# ADSP-2183xW_HPC register map
Vendor: Analog Devices; Series: ADSP-2183xW_HPC; File version: 3.0.3.517
CPU: 
Registers are 32-bit, read-write, reset 0x0 unless marked. A register's access mark holds for its fields unless they carry their own. Offsets are from the block's base; [hi:lo] are bit positions; {n}, {i} and the like mark numbered series.

## CSETR1
Base 0x3110A000
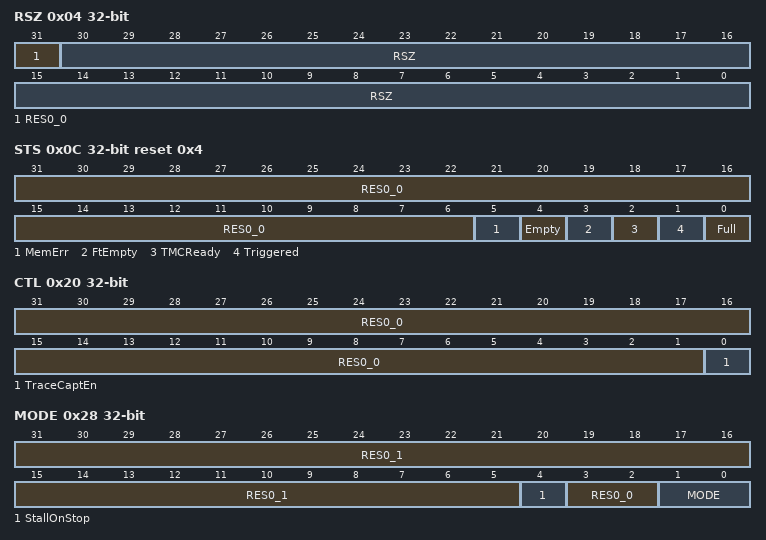
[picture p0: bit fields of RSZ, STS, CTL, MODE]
0x04 RSZ — RAM Size register.
  [31] RES0_0 range 0x00000000..0x00000001, [30:0] RSZ range 0x00000000..0x7FFFFFFF
0x0C STS reset 0x4 — Status register.
  [31:6] RES0_0 range 0x00000000..0x03FFFFFF, [5] MemErr range 0x00000000..0x00000001, [4] Empty ro, [3] FtEmpty ro, [2] TMCReady ro, [1] Triggered ro, [0] Full range 0x00000000..0x00000001
0x10 RRD — RAM Read Data register.
  [31:0] RRD ro
0x14 RRP — RAM Read Pointer register.
  [31:0] RRP range 0x00000000..0xFFFFFFFF
0x18 RWP — RAM Write Pointer register.
  [31:0] RWP range 0x00000000..0xFFFFFFFF
0x1C TRG — Trigger Counter register.
  [31:0] TRG range 0x00000000..0xFFFFFFFF
0x20 CTL — Control Register.
  [31:1] RES0_0 range 0x00000000..0x7FFFFFFF, [0] TraceCaptEn range 0x00000000..0x00000001
0x24 RWD — RAM Write Data register.
  [31:0] RWD wo range 0x00000000..0xFFFFFFFF
0x28 MODE
  [31:5] RES0_1 range 0x00000000..0x07FFFFFF, [4] StallOnStop range 0x00000000..0x00000001, [3:2] RES0_0 range 0x00000000..0x00000003, [1:0] MODE range 0x00000000..0x00000003
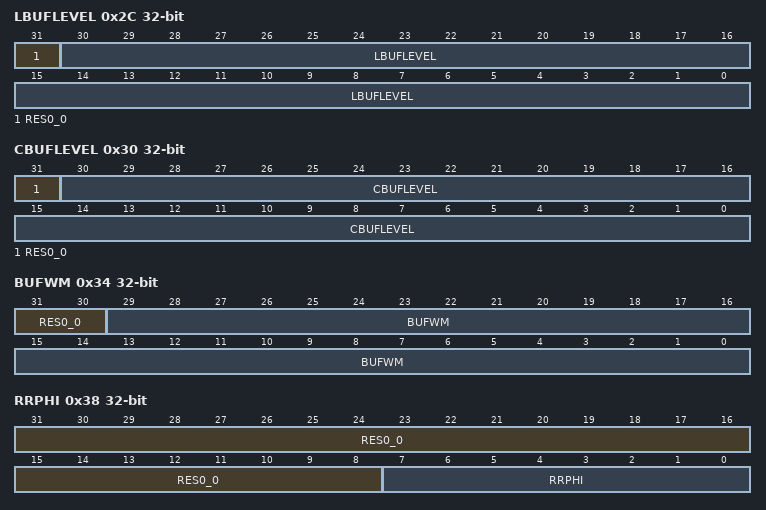
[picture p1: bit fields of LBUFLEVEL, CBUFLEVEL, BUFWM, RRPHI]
0x2C LBUFLEVEL — Latched Buffer Fill Level.
  [31] RES0_0 ro, [30:0] LBUFLEVEL ro
0x30 CBUFLEVEL — Current Buffer Fill Level.
  [31] RES0_0 ro, [30:0] CBUFLEVEL ro
0x34 BUFWM — Buffer Level Water Mark.
  [31:30] RES0_0 range 0x00000000..0x00000003, [29:0] BUFWM range 0x00000000..0x3FFFFFFF
0x38 RRPHI — RAM Read Pointer High register.
  [31:8] RES0_0 range 0x00000000..0x00FFFFFF, [7:0] RRPHI range 0x00000000..0x000000FF
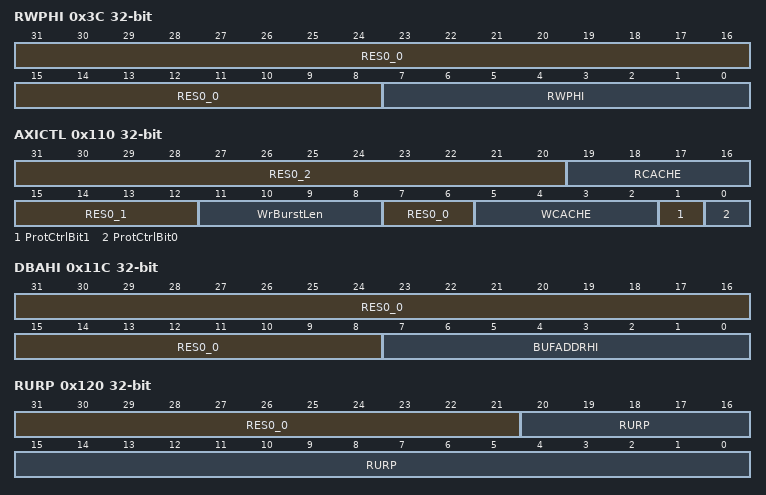
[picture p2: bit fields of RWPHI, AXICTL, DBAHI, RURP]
0x3C RWPHI — RAM Write Pointer High register.
  [31:8] RES0_0 range 0x00000000..0x00FFFFFF, [7:0] RWPHI range 0x00000000..0x000000FF
0x110 AXICTL — AXI Control Register.
  [31:20] RES0_2 range 0x00000000..0x00000FFF, [19:16] RCACHE range 0x00000000..0x0000000F, [15:12] RES0_1 range 0x00000000..0x0000000F, [11:8] WrBurstLen range 0x00000000..0x0000000F, [7:6] RES0_0 range 0x00000000..0x00000003, [5:2] WCACHE range 0x00000000..0x0000000F, [1] ProtCtrlBit1 range 0x00000000..0x00000001, [0] ProtCtrlBit0 range 0x00000000..0x00000001
0x118 DBALO — Data Buffer Address Low register.
  [31:0] BUFADDRLO range 0x00000000..0xFFFFFFFF
0x11C DBAHI — Data Buffer Address HIGH register.
  [31:8] RES0_0 range 0x00000000..0x00FFFFFF, [7:0] BUFADDRHI range 0x00000000..0x000000FF
0x120 RURP — RAM Update Read Pointer register.
  [31:21] RES0_0 wo range 0x00000000..0x000007FF, [20:0] RURP wo range 0x00000000..0x001FFFFF
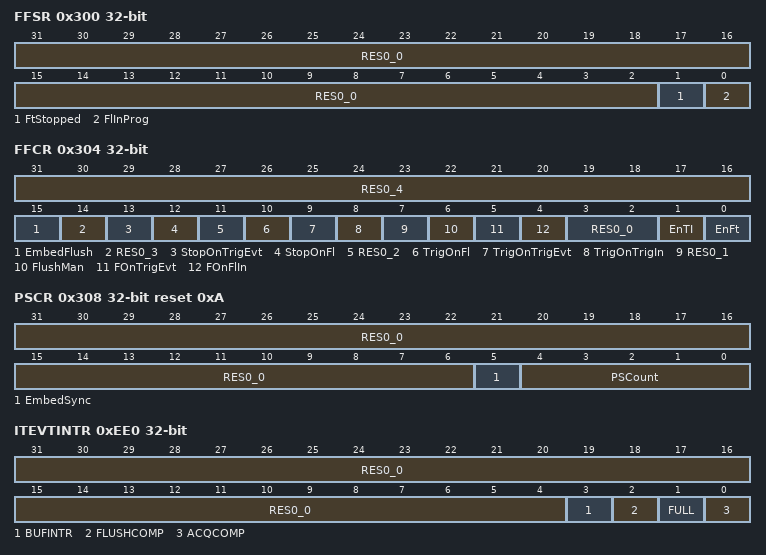
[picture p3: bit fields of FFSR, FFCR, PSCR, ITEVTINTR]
0x300 FFSR — Formatter and Flush Status Register.
  [31:2] RES0_0 ro, [1] FtStopped ro, [0] FlInProg ro
0x304 FFCR — Formatter and Flush Control Register.
  [31:16] RES0_4 range 0x00000000..0x0000FFFF, [15] EmbedFlush range 0x00000000..0x00000001, [14] RES0_3 range 0x00000000..0x00000001, [13] StopOnTrigEvt range 0x00000000..0x00000001, [12] StopOnFl range 0x00000000..0x00000001, [11] RES0_2 range 0x00000000..0x00000001, [10] TrigOnFl range 0x00000000..0x00000001, [9] TrigOnTrigEvt range 0x00000000..0x00000001, [8] TrigOnTrigIn range 0x00000000..0x00000001, [7] RES0_1 range 0x00000000..0x00000001, [6] FlushMan range 0x00000000..0x00000001, [5] FOnTrigEvt range 0x00000000..0x00000001, [4] FOnFlIn range 0x00000000..0x00000001, [3:2] RES0_0 range 0x00000000..0x00000003, [1] EnTI range 0x00000000..0x00000001, [0] EnFt range 0x00000000..0x00000001
0x308 PSCR reset 0xA — Periodic Synchronization Counter Register.
  [31:6] RES0_0 range 0x00000000..0x03FFFFFF, [5] EmbedSync range 0x00000000..0x00000001, [4:0] PSCount range 0x00000000..0x0000001F
0xEE0 ITEVTINTR — Integration Test Event and Interrupt Control Register.
  [31:4] RES0_0 wo range 0x00000000..0x0FFFFFFF, [3] BUFINTR wo range 0x00000000..0x00000001, [2] FLUSHCOMP wo range 0x00000000..0x00000001, [1] FULL wo range 0x00000000..0x00000001, [0] ACQCOMP wo range 0x00000000..0x00000001
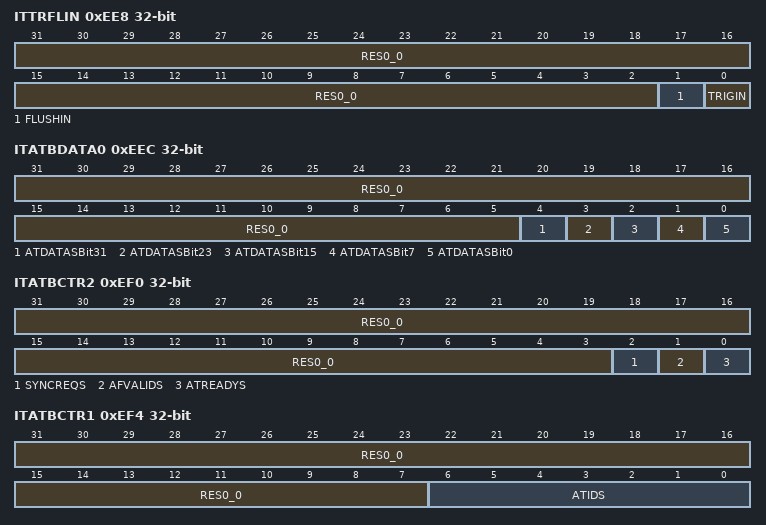
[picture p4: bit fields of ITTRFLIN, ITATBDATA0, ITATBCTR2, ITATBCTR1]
0xEE8 ITTRFLIN — Integration Test Trigger In and Flush In register.
  [31:2] RES0_0 ro, [1] FLUSHIN ro, [0] TRIGIN ro
0xEEC ITATBDATA0 — Integration Test ATB Data 0 Register.
  [31:5] RES0_0 ro, [4] ATDATASBit31 ro, [3] ATDATASBit23 ro, [2] ATDATASBit15 ro, [1] ATDATASBit7 ro, [0] ATDATASBit0 ro
0xEF0 ITATBCTR2 — Integration Test ATB Control 2 Register.
  [31:3] RES0_0 wo range 0x00000000..0x1FFFFFFF, [2] SYNCREQS wo range 0x00000000..0x00000001, [1] AFVALIDS wo range 0x00000000..0x00000001, [0] ATREADYS wo range 0x00000000..0x00000001
0xEF4 ITATBCTR1 — Integration Test ATB Control 1 Register.
  [31:7] RES0_0 ro, [6:0] ATIDS ro
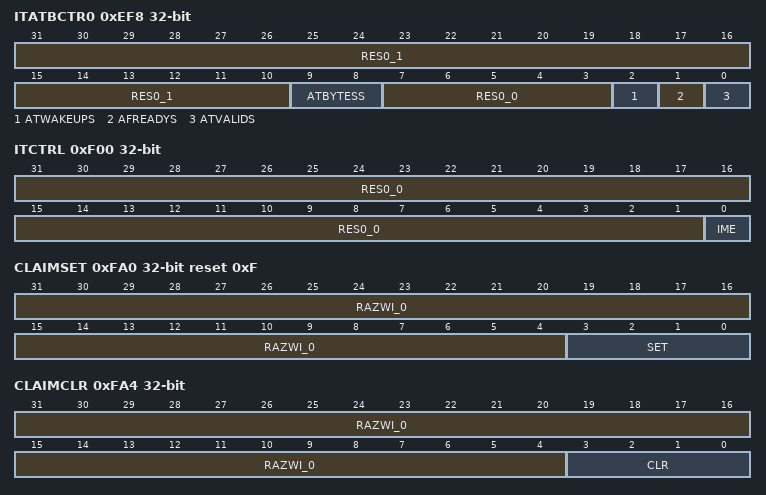
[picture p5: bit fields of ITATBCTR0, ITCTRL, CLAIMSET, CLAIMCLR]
0xEF8 ITATBCTR0 — Integration Test ATB Control 0 Register.
  [31:10] RES0_1 ro, [9:8] ATBYTESS ro, [7:3] RES0_0 ro, [2] ATWAKEUPS ro, [1] AFREADYS ro, [0] ATVALIDS ro
0xF00 ITCTRL — Integration Mode Control Register.
  [31:1] RES0_0 range 0x00000000..0x7FFFFFFF, [0] IME range 0x00000000..0x00000001
0xFA0 CLAIMSET reset 0xF — Claim Tag Set Register.
  [31:4] RAZWI_0 range 0x00000000..0x0FFFFFFF, [3:0] SET range 0x00000000..0x0000000F
0xFA4 CLAIMCLR — Claim Tag Clear Register.
  [31:4] RAZWI_0 range 0x00000000..0x0FFFFFFF, [3:0] CLR range 0x00000000..0x0000000F
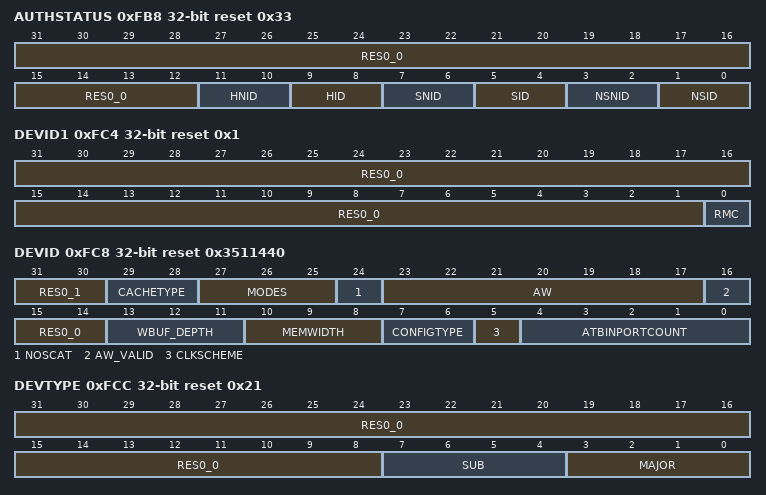
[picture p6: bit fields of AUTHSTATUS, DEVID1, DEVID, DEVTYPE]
0xFB8 AUTHSTATUS reset 0x33 — Authentication Status Register.
  [31:12] RES0_0 ro, [11:10] HNID ro, [9:8] HID ro, [7:6] SNID ro, [5:4] SID ro, [3:2] NSNID ro, [1:0] NSID ro
0xFC4 DEVID1 reset 0x1 — Device Configuration Register 1.
  [31:1] RES0_0 ro, [0] RMC ro
0xFC8 DEVID reset 0x3511440 — Device Configuration Register.
  [31:30] RES0_1 ro, [29:28] CACHETYPE ro, [27:25] MODES ro, [24] NOSCAT ro, [23:17] AW ro, [16] AW_VALID ro, [15:14] RES0_0 ro, [13:11] WBUF_DEPTH ro, [10:8] MEMWIDTH ro, [7:6] CONFIGTYPE ro, [5] CLKSCHEME ro, [4:0] ATBINPORTCOUNT ro
0xFCC DEVTYPE reset 0x21 — Device Type Identifier Register.
  [31:8] RES0_0 ro, [7:4] SUB ro, [3:0] MAJOR ro
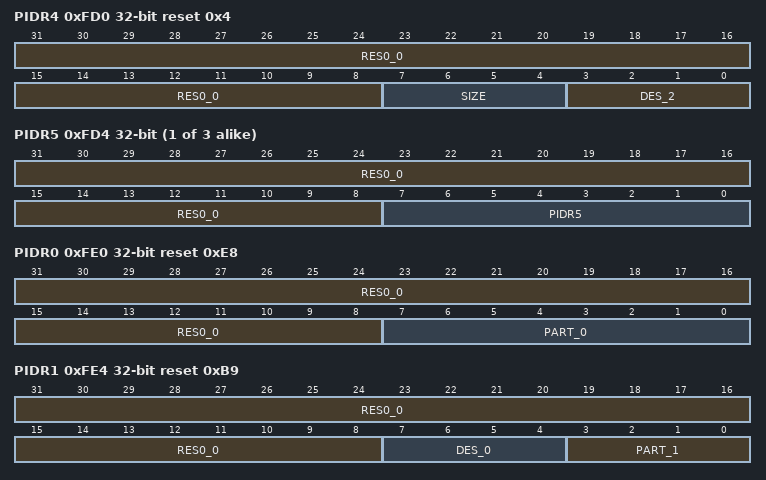
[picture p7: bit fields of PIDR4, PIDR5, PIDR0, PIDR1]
0xFD0 PIDR4 reset 0x4 — Peripheral Identification Register 4.
  [31:8] RES0_0 ro, [7:4] SIZE ro, [3:0] DES_2 ro
{0xFC0+4i} PIDR{i} (i=5..7) — Peripheral Identification Register {i}.
  [31:8] RES0_0 ro, [7:0] PIDR{i} ro
0xFE0 PIDR0 reset 0xE8 — Peripheral Identification Register 0.
  [31:8] RES0_0 ro, [7:0] PART_0 ro
0xFE4 PIDR1 reset 0xB9 — Peripheral Identification Register 1.
  [31:8] RES0_0 ro, [7:4] DES_0 ro, [3:0] PART_1 ro
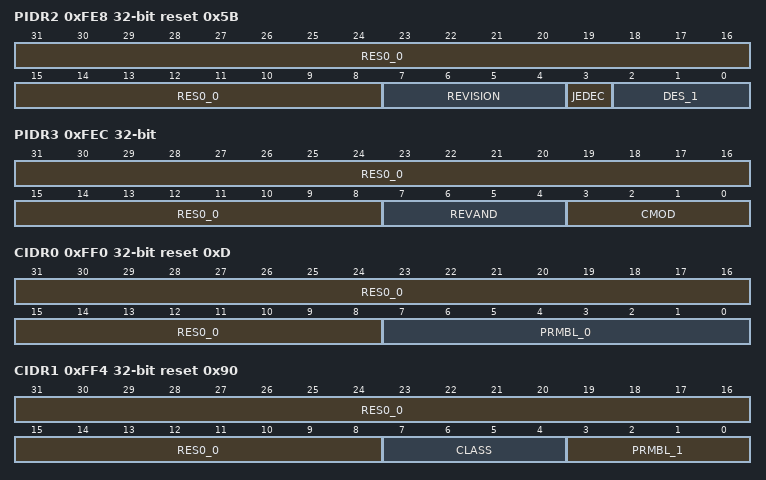
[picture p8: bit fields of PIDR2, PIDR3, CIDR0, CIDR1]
0xFE8 PIDR2 reset 0x5B — Peripheral Identification Register 2.
  [31:8] RES0_0 ro, [7:4] REVISION ro, [3] JEDEC ro, [2:0] DES_1 ro
0xFEC PIDR3 — Peripheral Identification Register 3.
  [31:8] RES0_0 ro, [7:4] REVAND ro, [3:0] CMOD ro
0xFF0 CIDR0 reset 0xD — Component Identification Register 0.
  [31:8] RES0_0 ro, [7:0] PRMBL_0 ro
0xFF4 CIDR1 reset 0x90 — Component Identification Register 1.
  [31:8] RES0_0 ro, [7:4] CLASS ro, [3:0] PRMBL_1 ro
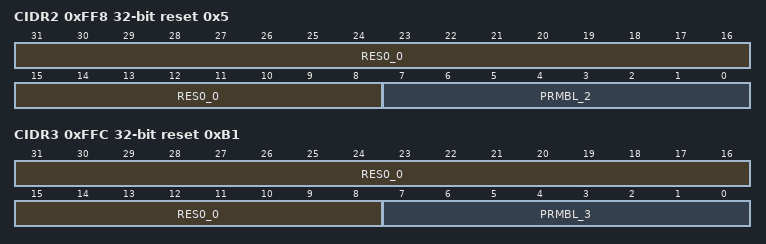
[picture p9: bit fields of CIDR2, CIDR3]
0xFF8 CIDR2 reset 0x5 — Component Identification Register 2.
  [31:8] RES0_0 ro, [7:0] PRMBL_2 ro
0xFFC CIDR3 reset 0xB1 — Component Identification Register 3.
  [31:8] RES0_0 ro, [7:0] PRMBL_3 ro
